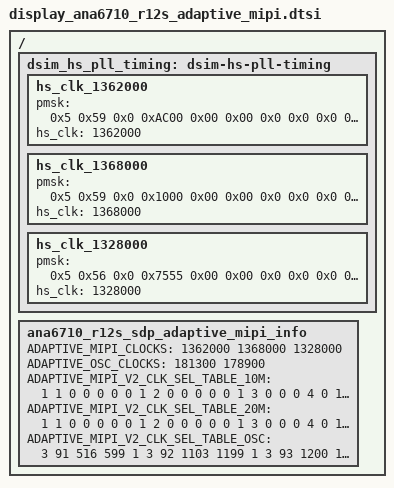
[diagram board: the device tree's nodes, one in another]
/*
 * SAMSUNG Panel Device Tree Source
 *
 * Copyright (c) Samsung Electronics Co., Ltd.
 *		http://www.samsung.com
 *
 * This program is free software; you can redistribute it and/or modify
 * it under the terms of the GNU General Public License version 2 as
 * published by the Free Software Foundation.
 */

#include <dt-bindings/display/rf-band-id.h>

/ {
	fragment@freq_hop {
		target-path = "/";
		__overlay__ {
			dsim_hs_pll_timing: dsim-hs-pll-timing {
				hs_clk_1362000 {
					pmsk = <
						0x5 0x59 0x0 0xAC00
						0x00 0x00 0x0 0x0
						0x0 0x0 0x0 0x0
						0x0 0x0
						>;
					hs_clk = <1362000>;
				};

				hs_clk_1368000 {
					pmsk = <
						0x5 0x59 0x0 0x1000
						0x00 0x00 0x0 0x0
						0x0 0x0 0x0 0x0
						0x0 0x0
						>;
					hs_clk = <1368000>;
				};

				hs_clk_1328000 {
					pmsk = <
						0x5 0x56 0x0 0x7555
						0x00 0x00 0x0 0x0
						0x0 0x0 0x0 0x0
						0x0 0x0
						>;
					hs_clk = <1328000>;
				};
			}; 

			ana6710_r12s_sdp_adaptive_mipi_info:
			ana6710_r12s_sdp_adaptive_mipi_info {
				/* TABLE: ADAPTIVE MIPI V2: MIPI CLOCKS [kbps] */
				ADAPTIVE_MIPI_CLOCKS = <
					  1362000
					  1368000
					  1328000
				>;

				/* TABLE: ADAPTIVE MIPI V2: OSC CLOCKS [khz] */
				ADAPTIVE_OSC_CLOCKS = <
					  181300
					  178900
				>;

				/* TABLE: ADAPTIVE MIPI V2: TABLE_10M */
				/* RAT BAND FROM END RATING_A RATING_B RATING_C */
				ADAPTIVE_MIPI_V2_CLK_SEL_TABLE_10M = <
					1	1	0	0	0	0	0
					1	2	0	0	0	0	0
					1	3	0	0	0	4	0
					1	4	0	0	0	0	80
					2	11	10562	10754	0	0	0
					2	11	10755	10824	0	0	4
					2	11	10825	10838	0	0	0
					2	12	9662	9924	0	0	0
					2	12	9925	9938	0	0	80
					2	13	1162	1219	0	0	0
					2	13	1220	1289	0	0	4
					2	13	1290	1453	0	0	0
					2	13	1454	1494	4	0	0
					2	13	1495	1513	4	4	0
					2	14	1537	1729	0	0	0
					2	14	1730	1738	0	0	4
					2	15	4357	4458	0	0	0
					2	16	4387	4413	0	0	0
					2	17	2237	2369	0	0	0
					2	17	2370	2439	0	0	40
					2	17	2440	2563	0	0	0
					2	18	2937	3088	0	0	0
					2	29	712	763	0	0	0
					3	91	0	409	0	0	0
					3	91	410	549	0	0	4
					3	91	550	599	0	0	0
					3	92	600	1149	0	0	0
					3	92	1150	1199	0	0	80
					3	93	1200	1339	0	0	0
					3	93	1340	1479	0	0	4
					3	93	1480	1807	0	0	0
					3	93	1808	1889	4	0	0
					3	93	1890	1947	4	4	0
					3	93	1948	1949	0	4	0
					3	94	1950	2359	0	0	0
					3	94	2360	2399	0	0	4
					3	95	2400	2649	0	0	0
					3	97	2750	3039	0	0	0
					3	97	3040	3179	0	0	40
					3	97	3180	3449	0	0	0
					3	98	3450	3799	0	0	0
					3	102	5010	5179	0	0	0
					3	103	5180	5279	0	0	0
					3	104	5280	5379	0	0	0
					3	107	5730	5849	0	0	0
					3	108	5850	5869	0	6	0
					3	108	5870	5999	0	0	0
					3	109	6000	6149	0	0	0
					3	110	6150	6449	0	0	0
					3	111	6450	6500	0	0	4
					3	111	6501	6599	0	0	0
					3	115	8040	8589	0	0	0
					3	115	8590	8689	0	0	80
					3	116	8690	8719	0	6	0
					3	116	8720	9039	0	0	0
					3	118	9210	9659	0	0	0
					3	119	9660	9769	0	0	0
					3	120	9770	9869	0	0	0
					3	122	9920	10269	0	0	0
					3	122	10270	10359	0	0	4
					3	124	36200	36349	0	0	0
					3	128	37750	37769	0	2	0
					3	128	37770	38249	0	0	0
					3	129	38250	38329	0	4	0
					3	129	38330	38649	0	0	0
					3	130	38650	39649	0	0	0
					3	131	39650	39659	0	0	2
					3	131	39660	40157	0	0	0
					3	131	40158	40269	2	0	0
					3	131	40270	40297	2	2	0
					3	131	40298	40409	0	2	0
					3	131	40410	41179	0	0	0
					3	131	41180	41319	0	0	40
					3	131	41320	41589	0	0	0
					3	132	41590	41710	40	0	0
					3	132	41711	41720	0	0	0
					3	132	41721	41860	0	40	0
					3	132	41861	42380	0	0	0
					3	132	42381	42520	0	0	2
					3	132	42521	43272	0	0	0
					3	132	43273	43412	2	0	0
					3	132	43413	43430	0	0	0
					3	132	43431	43570	0	2	0
					3	132	43571	43589	0	0	0
					3	138	55240	55422	0	0	0
					3	138	55423	55562	2	0	0
					3	138	55563	55580	0	0	0
					3	138	55581	55720	0	2	0
					3	138	55721	56739	0	0	0
					3	156	66436	66845	0	0	0
					3	156	66846	66985	0	0	4
					3	156	66986	67335	0	0	0
					3	161	68586	68935	0	0	0
					4	51	0	0	0	0	0
					4	52	0	0	2	4	0
					4	53	0	0	0	0	0
					4	54	0	0	0	6	0
					4	55	0	0	0	0	1
					4	56	0	0	0	4	0
					5	61	0	0	0	0	0
					5	62	0	0	0	0	80
					5	71	0	0	6	12	0
					7	256	422000	430180	0	0	0
					7	256	430181	432980	0	0	4
					7	256	432981	433980	0	0	0
					7	257	386000	396980	0	0	0
					7	257	396981	397980	0	0	80
					7	258	361000	363780	0	0	0
					7	258	363781	366580	0	0	4
					7	258	366581	373140	0	0	0
					7	258	373141	374780	4	0	0
					7	258	374781	375940	4	4	0
					7	258	375941	375980	0	4	0
					7	260	173800	178780	0	0	0
					7	262	524000	529780	0	0	0
					7	262	529781	532580	0	0	40
					7	262	532581	538000	0	0	0
					7	263	185000	191980	0	0	0
					7	267	145800	149200	0	0	0
					7	269	151600	153580	0	0	0
					7	275	158200	164180	0	0	0
					7	280	386000	396980	0	0	0
					7	280	396981	398980	0	0	80
					7	283	151600	160580	0	0	0
					7	284	143400	145580	0	0	0
					7	285	470000	471980	0	0	0
					7	293	514000	514380	0	2	0
					7	293	514381	523980	0	0	0
					7	295	460000	480000	0	0	0
					7	296	499200	499380	0	0	2
					7	296	499381	509340	0	0	0
					7	296	509341	511580	2	0	0
					7	296	511581	512140	2	2	0
					7	296	512141	514380	0	2	0
					7	296	514381	529780	0	0	0
					7	296	529781	532580	0	0	40
					7	296	532581	537980	0	0	0
					7	303	636667	637867	0	0	0
					7	303	637868	638807	2	0	0
					7	303	638808	638927	0	0	0
					7	303	638928	639847	0	2	0
					7	303	639848	646666	0	0	0
					7	321	422000	430180	0	0	0
					7	321	430181	432980	0	0	4
					7	321	432981	439980	0	0	0
					7	326	123400	130380	0	0	0
					7	332	620000	620860	0	0	0
					7	332	620861	621780	0	0	40
					7	332	621781	626520	0	0	0
					7	332	626521	627460	40	0	0
					7	332	627461	627520	0	0	0
					7	332	627521	628460	0	40	0
					7	332	628461	631920	0	0	0
					7	332	631921	632860	0	0	2
					7	332	632861	637880	0	0	0
					7	332	637881	638800	2	0	0
					7	332	638801	638920	0	0	0
					7	332	638921	639860	0	2	0
					7	332	639861	654060	0	0	0
					7	332	654061	654980	0	0	2
					7	332	654981	660580	0	0	0
					7	332	660581	661500	2	0	0
					7	332	661501	661720	0	0	0
					7	332	661721	662660	0	2	0
					7	332	662661	665120	0	0	0
					7	332	665121	666060	0	0	40
					7	332	666061	671920	0	0	0
					7	332	671921	672860	40	0	0
					7	332	672861	673120	0	0	0
					7	332	673121	674060	0	40	0
					7	332	674061	676200	0	0	0
					7	332	676201	677120	0	0	2
					7	332	677121	680000	0	0	0
					7	333	620000	620860	0	0	0
					7	333	620861	621780	0	0	40
					7	333	621781	626520	0	0	0
					7	333	626521	627460	40	0	0
					7	333	627461	627520	0	0	0
					7	333	627521	628460	0	40	0
					7	333	628461	631920	0	0	0
					7	333	631921	632860	0	0	2
					7	333	632861	637880	0	0	0
					7	333	637881	638800	2	0	0
					7	333	638801	638920	0	0	0
					7	333	638921	639860	0	2	0
					7	333	639861	653333	0	0	0
					7	334	693334	698334	0	0	0
					7	334	698335	699254	0	0	2
					7	334	699255	705974	0	0	0
					7	334	705975	706914	2	0	0
					7	334	706915	707334	0	0	0
					7	334	707335	708254	0	2	0
					7	334	708255	709394	0	0	0
					7	334	709395	710314	0	0	40
					7	334	710315	717334	0	0	0
					7	334	717335	718254	40	0	0
					7	334	718255	718734	0	0	0
					7	334	718735	719654	0	40	0
					7	334	719655	720454	0	0	0
					7	334	720455	721394	0	0	2
					7	334	721395	728674	0	0	0
					7	334	728675	729614	2	0	0
					7	334	729615	730134	0	0	0
					7	334	730135	731054	0	2	0
					7	334	731055	733333	0	0	0
				>;

				/* TABLE: ADAPTIVE MIPI V2: TABLE_20M */
				/* RAT BAND FROM END RATING_A RATING_B RATING_C */
				ADAPTIVE_MIPI_V2_CLK_SEL_TABLE_20M = <
					1	1	0	0	0	0	0
					1	2	0	0	0	0	0
					1	3	0	0	0	4	0
					1	4	0	0	0	0	80
					2	11	10562	10754	0	0	0
					2	11	10755	10824	0	0	4
					2	11	10825	10838	0	0	0
					2	12	9662	9924	0	0	0
					2	12	9925	9938	0	0	80
					2	13	1162	1219	0	0	0
					2	13	1220	1289	0	0	4
					2	13	1290	1453	0	0	0
					2	13	1454	1494	4	0	0
					2	13	1495	1513	4	4	0
					2	14	1537	1729	0	0	0
					2	14	1730	1738	0	0	4
					2	15	4357	4458	0	0	0
					2	16	4387	4413	0	0	0
					2	17	2237	2369	0	0	0
					2	17	2370	2439	0	0	40
					2	17	2440	2563	0	0	0
					2	18	2937	3088	0	0	0
					2	29	712	763	0	0	0
					3	91	0	359	0	0	0
					3	91	360	599	0	0	4
					3	92	600	1099	0	0	0
					3	92	1100	1199	0	0	80
					3	93	1200	1289	0	0	0
					3	93	1290	1529	0	0	4
					3	93	1530	1757	0	0	0
					3	93	1758	1839	4	0	0
					3	93	1840	1949	4	4	0
					3	94	1950	2309	0	0	0
					3	94	2310	2399	0	0	4
					3	95	2400	2649	0	0	0
					3	97	2750	2989	0	0	0
					3	97	2990	3229	0	0	40
					3	97	3230	3449	0	0	0
					3	98	3450	3799	0	0	0
					3	102	5010	5179	0	0	0
					3	103	5180	5279	0	0	0
					3	104	5280	5379	0	0	0
					3	107	5730	5849	0	0	0
					3	108	5850	5882	6	6	0
					3	108	5883	5919	0	6	0
					3	108	5920	5999	0	0	0
					3	109	6000	6149	0	0	0
					3	110	6150	6419	0	0	0
					3	110	6420	6449	0	0	6
					3	111	6450	6550	0	0	4
					3	111	6551	6599	0	0	0
					3	115	8040	8539	0	0	0
					3	115	8540	8689	0	0	80
					3	116	8690	8732	6	6	0
					3	116	8733	8769	0	6	0
					3	116	8770	9039	0	0	0
					3	118	9210	9659	0	0	0
					3	119	9660	9769	0	0	0
					3	120	9770	9869	0	0	0
					3	122	9920	10219	0	0	0
					3	122	10220	10359	0	0	4
					3	124	36200	36349	0	0	0
					3	128	37750	37819	0	2	0
					3	128	37820	38249	0	0	0
					3	129	38250	38297	4	4	0
					3	129	38298	38379	0	4	0
					3	129	38380	38649	0	0	0
					3	130	38650	39649	0	0	0
					3	131	39650	39709	0	0	2
					3	131	39710	40107	0	0	0
					3	131	40108	40219	2	0	0
					3	131	40220	40347	2	2	0
					3	131	40348	40459	0	2	0
					3	131	40460	41129	0	0	0
					3	131	41130	41369	0	0	40
					3	131	41370	41589	0	0	0
					3	132	41590	41670	40	0	0
					3	132	41671	41760	40	40	0
					3	132	41761	41910	0	40	0
					3	132	41911	42330	0	0	0
					3	132	42331	42570	0	0	2
					3	132	42571	43222	0	0	0
					3	132	43223	43380	2	0	0
					3	132	43381	43462	2	2	0
					3	132	43463	43589	0	2	0
					3	138	55240	55372	0	0	0
					3	138	55373	55530	2	0	0
					3	138	55531	55612	2	2	0
					3	138	55613	55770	0	2	0
					3	138	55771	56739	0	0	0
					3	156	66436	66795	0	0	0
					3	156	66796	67035	0	0	4
					3	156	67036	67335	0	0	0
					3	161	68586	68935	0	0	0
					4	51	0	0	0	0	0
					4	52	0	0	2	4	0
					4	53	0	0	0	0	0
					4	54	0	0	2	6	0
					4	55	0	0	0	0	1
					4	56	0	0	0	4	0
					5	61	0	0	0	0	0
					5	62	0	0	0	0	80
					5	71	0	0	6	12	0
					7	256	422000	429180	0	0	0
					7	256	429181	433980	0	0	4
					7	257	386000	395980	0	0	0
					7	257	395981	397980	0	0	80
					7	258	361000	362780	0	0	0
					7	258	362781	367580	0	0	4
					7	258	367581	372140	0	0	0
					7	258	372141	373780	4	0	0
					7	258	373781	375980	4	4	0
					7	260	173800	178780	0	0	0
					7	262	524000	528780	0	0	0
					7	262	528781	533580	0	0	40
					7	262	533581	538000	0	0	0
					7	263	185000	191980	0	0	0
					7	267	145800	149200	0	0	0
					7	269	151600	153580	0	0	0
					7	275	158200	163580	0	0	0
					7	275	163581	164180	0	0	6
					7	280	386000	395980	0	0	0
					7	280	395981	398980	0	0	80
					7	283	151600	160580	0	0	0
					7	284	143400	145580	0	0	0
					7	285	470000	471980	0	0	0
					7	293	514000	515380	0	2	0
					7	293	515381	523980	0	0	0
					7	295	460000	480000	0	0	0
					7	296	499200	500380	0	0	2
					7	296	500381	508340	0	0	0
					7	296	508341	510580	2	0	0
					7	296	510581	513140	2	2	0
					7	296	513141	515380	0	2	0
					7	296	515381	528780	0	0	0
					7	296	528781	533580	0	0	40
					7	296	533581	537980	0	0	0
					7	303	636667	637547	0	0	0
					7	303	637548	638587	2	0	0
					7	303	638588	639147	2	2	0
					7	303	639148	640187	0	2	0
					7	303	640188	646666	0	0	0
					7	321	422000	429180	0	0	0
					7	321	429181	433980	0	0	4
					7	321	433981	439980	0	0	0
					7	326	123400	130380	0	0	0
					7	332	620000	620520	0	0	0
					7	332	620521	622120	0	0	40
					7	332	622121	626200	0	0	0
					7	332	626201	627200	40	0	0
					7	332	627201	627780	40	40	0
					7	332	627781	628780	0	40	0
					7	332	628781	631600	0	0	0
					7	332	631601	633180	0	0	2
					7	332	633181	637540	0	0	0
					7	332	637541	638600	2	0	0
					7	332	638601	639140	2	2	0
					7	332	639141	640180	0	2	0
					7	332	640181	653720	0	0	0
					7	332	653721	655320	0	0	2
					7	332	655321	660240	0	0	0
					7	332	660241	661400	2	0	0
					7	332	661401	661840	2	2	0
					7	332	661841	662980	0	2	0
					7	332	662981	664800	0	0	0
					7	332	664801	666380	0	0	40
					7	332	666381	671600	0	0	0
					7	332	671601	672800	40	0	0
					7	332	672801	673180	40	40	0
					7	332	673181	674380	0	40	0
					7	332	674381	675860	0	0	0
					7	332	675861	677460	0	0	2
					7	332	677461	680000	0	0	0
					7	333	620000	620520	0	0	0
					7	333	620521	622120	0	0	40
					7	333	622121	626200	0	0	0
					7	333	626201	627200	40	0	0
					7	333	627201	627780	40	40	0
					7	333	627781	628780	0	40	0
					7	333	628781	631600	0	0	0
					7	333	631601	633180	0	0	2
					7	333	633181	637540	0	0	0
					7	333	637541	638600	2	0	0
					7	333	638601	639140	2	2	0
					7	333	639141	640180	0	2	0
					7	333	640181	653333	0	0	0
					7	334	693334	697994	0	0	0
					7	334	697995	699594	0	0	2
					7	334	699595	705634	0	0	0
					7	334	705635	706994	2	0	0
					7	334	706995	707234	2	2	0
					7	334	707235	708594	0	2	0
					7	334	708595	709054	0	0	0
					7	334	709055	710654	0	0	40
					7	334	710655	716994	0	0	0
					7	334	716995	718394	40	0	0
					7	334	718395	718594	40	40	0
					7	334	718595	719994	0	40	0
					7	334	719995	720134	0	0	0
					7	334	720135	721714	0	0	2
					7	334	721715	728334	0	0	0
					7	334	728335	729794	2	0	0
					7	334	729795	729934	2	2	0
					7	334	729935	731394	0	2	0
					7	334	731395	733333	0	0	0
				>;
				/* TABLE: ADAPTIVE MIPI V2: TABLE_OSC */
				/* RAT BAND FROM END OSC_IDX */
				ADAPTIVE_MIPI_V2_CLK_SEL_TABLE_OSC = <
					3	91	516		599		1
					3	92	1103	1199	1
					3	93	1200	1419	1
					3	95	2635	2649	1
					3	102	5010	5111	1
					3	107	5730	5781	1
					3	115	8543	8689	1
					3	116	9025	9039	1
					3	119	9660	9769	1
					3	120	9770	9869	1
					3	122	9920	10043	1
					3	130	39079	39358	1
					3	131	39932	40211	1
					3	138	55861	56140	1
					3	156	66952	67231	1
					7	256	432301	433980	1
					7	257	396041	397980	1
					7	258	361000	365380	1
					7	260	178481	178780	1
					7	267	145800	147820	1
					7	280	396041	398980	1
				>;
			};
		};
	};
};
